# STM32H745BGT6@M4 register map
File version: 1.0
Registers are 32-bit, access not given, reset 0x0 unless marked. A register's access mark holds for its fields unless they carry their own. Offsets are from the block's base; [hi:lo] are bit positions.

## TIM6
Base 0x40001000
Same registers: TIM7 0x40001400
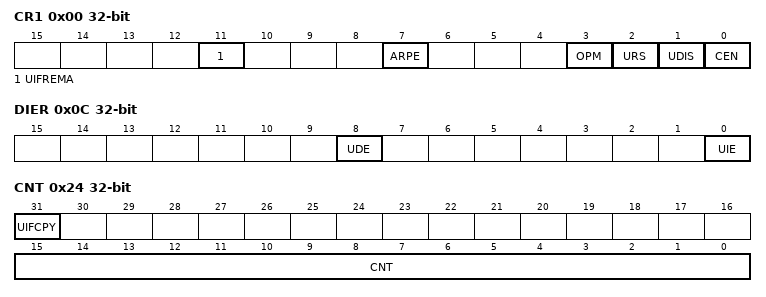
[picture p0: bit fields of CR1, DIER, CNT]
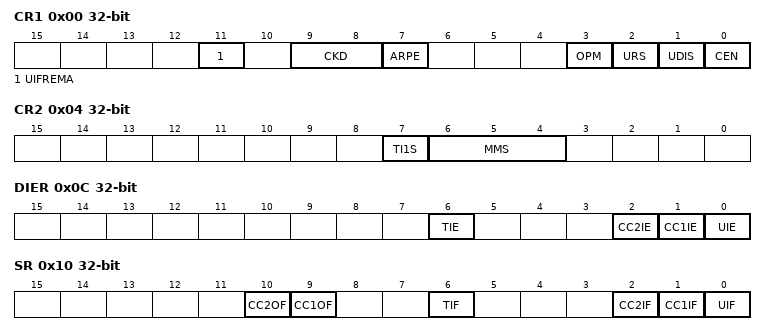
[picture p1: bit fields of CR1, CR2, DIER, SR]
0x00 CR1
  [11] UIFREMA, [7] ARPE, [3] OPM, [2] URS, [1] UDIS, [0] CEN
0x04 CR2
  [6:4] MMS
0x0C DIER
  [8] UDE, [0] UIE
0x10 SR
  [0] UIF
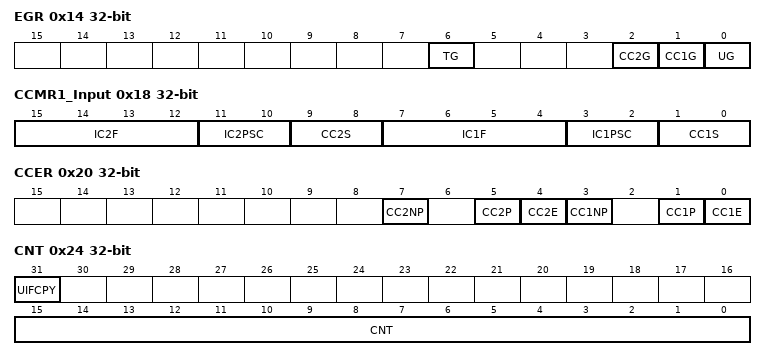
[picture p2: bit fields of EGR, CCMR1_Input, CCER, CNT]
0x14 EGR
  [0] UG
0x24 CNT
  [31] UIFCPY, [15:0] CNT
0x28 PSC
  [15:0] PSC
0x2C ARR
  [15:0] ARR

## TIM12
Base 0x40001800
0x00 CR1
  [11] UIFREMA, [9:8] CKD, [7] ARPE, [3] OPM, [2] URS, [1] UDIS, [0] CEN
0x04 CR2
  [7] TI1S, [6:4] MMS
0x08 SMCR
  [7] MSM, [21:4] TS, [16:0] SMS
0x0C DIER
  [6] TIE, [2] CC2IE, [1] CC1IE, [0] UIE
0x10 SR
  [10] CC2OF, [9] CC1OF, [6] TIF, [2] CC2IF, [1] CC1IF, [0] UIF
0x14 EGR
  [6] TG, [2] CC2G, [1] CC1G, [0] UG
0x18 CCMR1_Output
  [24:12] OC2M, [11] OC2PE, [10] OC2FE, [9:8] CC2S, [16:4] OC1M, [3] OC1PE, [2] OC1FE, [1:0] CC1S
0x18 CCMR1_Input
  [15:12] IC2F, [11:10] IC2PSC, [9:8] CC2S, [7:4] IC1F, [3:2] IC1PSC, [1:0] CC1S
0x20 CCER
  [7] CC2NP, [5] CC2P, [4] CC2E, [3] CC1NP, [1] CC1P, [0] CC1E
0x24 CNT
  [31] UIFCPY, [15:0] CNT
0x28 PSC
  [15:0] PSC
0x2C ARR
  [15:0] ARR
0x34 CCR1
  [15:0] CCR1
0x38 CCR2
  [15:0] CCR2
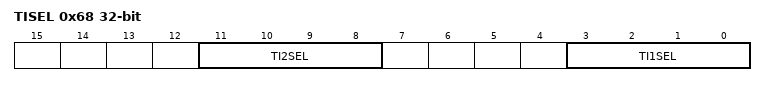
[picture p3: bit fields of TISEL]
0x68 TISEL
  [11:8] TI2SEL, [3:0] TI1SEL

## TIM13
Base 0x40001C00
Same registers: TIM14 0x40002000
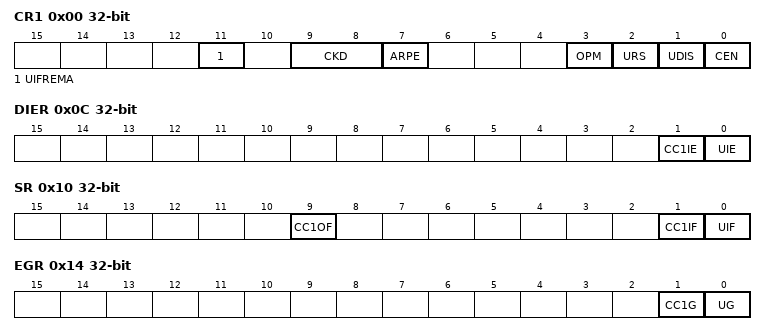
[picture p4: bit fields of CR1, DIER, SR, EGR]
0x00 CR1
  [11] UIFREMA, [9:8] CKD, [7] ARPE, [3] OPM, [2] URS, [1] UDIS, [0] CEN
0x0C DIER
  [1] CC1IE, [0] UIE
0x10 SR
  [9] CC1OF, [1] CC1IF, [0] UIF
0x14 EGR
  [1] CC1G, [0] UG
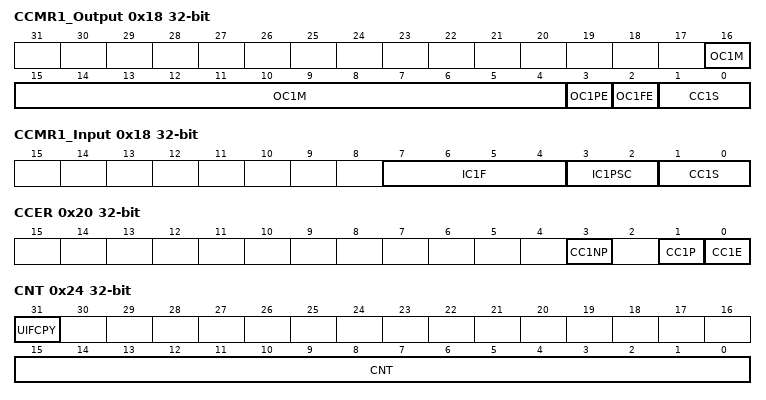
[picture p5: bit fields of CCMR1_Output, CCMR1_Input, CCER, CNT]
0x18 CCMR1_Output
  [16:4] OC1M, [3] OC1PE, [2] OC1FE, [1:0] CC1S
0x18 CCMR1_Input
  [7:4] IC1F, [3:2] IC1PSC, [1:0] CC1S
0x20 CCER
  [3] CC1NP, [1] CC1P, [0] CC1E
0x24 CNT
  [31] UIFCPY, [15:0] CNT
0x28 PSC
  [15:0] PSC
0x2C ARR
  [15:0] ARR
0x34 CCR1
  [15:0] CCR1
0x68 TISEL
  [3:0] TI1SEL

## LPTIM1
Base 0x40002400
Same registers: LPTIM2 0x58002400, LPTIM4 0x58002C00, LPTIM5 0x58003000
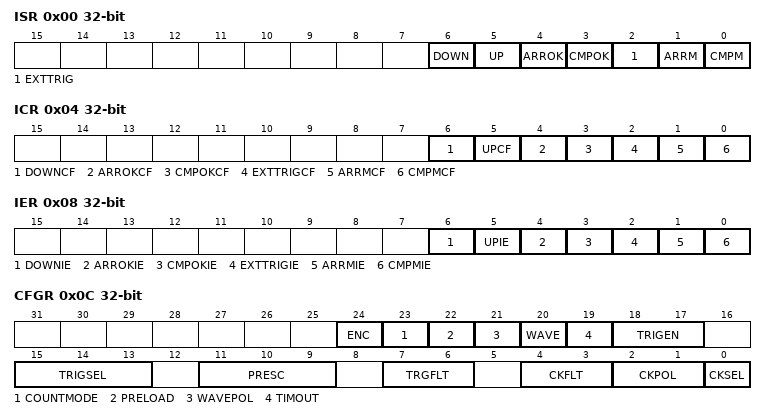
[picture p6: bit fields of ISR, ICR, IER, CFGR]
0x00 ISR
  [6] DOWN, [5] UP, [4] ARROK, [3] CMPOK, [2] EXTTRIG, [1] ARRM, [0] CMPM
0x04 ICR
  [6] DOWNCF, [5] UPCF, [4] ARROKCF, [3] CMPOKCF, [2] EXTTRIGCF, [1] ARRMCF, [0] CMPMCF
0x08 IER
  [6] DOWNIE, [5] UPIE, [4] ARROKIE, [3] CMPOKIE, [2] EXTTRIGIE, [1] ARRMIE, [0] CMPMIE
0x0C CFGR
  [24] ENC, [23] COUNTMODE, [22] PRELOAD, [21] WAVEPOL, [20] WAVE, [19] TIMOUT, [18:17] TRIGEN, [15:13] TRIGSEL, [11:9] PRESC, [7:6] TRGFLT, [4:3] CKFLT, [2:1] CKPOL, [0] CKSEL
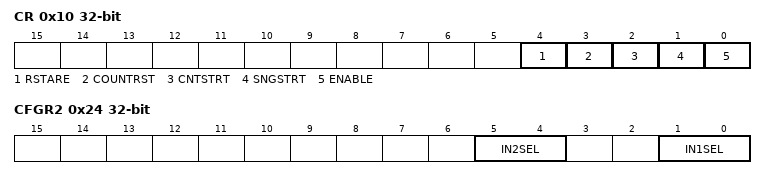
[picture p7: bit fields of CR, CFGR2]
0x10 CR
  [4] RSTARE, [3] COUNTRST, [2] CNTSTRT, [1] SNGSTRT, [0] ENABLE
0x14 CMP
  [15:0] CMP
0x18 ARR
  [15:0] ARR
0x1C CNT
  [15:0] CNT
0x24 CFGR2
  [5:4] IN2SEL, [1:0] IN1SEL

## LPTIM3
Base 0x58002800
Registers as LPTIM1; these are added or differ:
0x24 CFGR2
  [1:0] IN1SEL

## WWDG2
Base 0x40002C00
Same registers: WWDG1 0x50003000
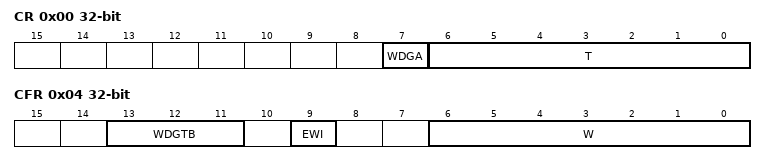
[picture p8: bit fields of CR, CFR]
0x00 CR
  [7] WDGA, [6:0] T
0x04 CFR
  [13:11] WDGTB, [9] EWI, [6:0] W
0x08 SR
  [0] EWIF

## SPI2
Base 0x40003800
Same registers: SPI3 0x40003C00, SPI1 0x40013000, SPI4 0x40013400, SPI5 0x40015000, SPI6 0x58001400
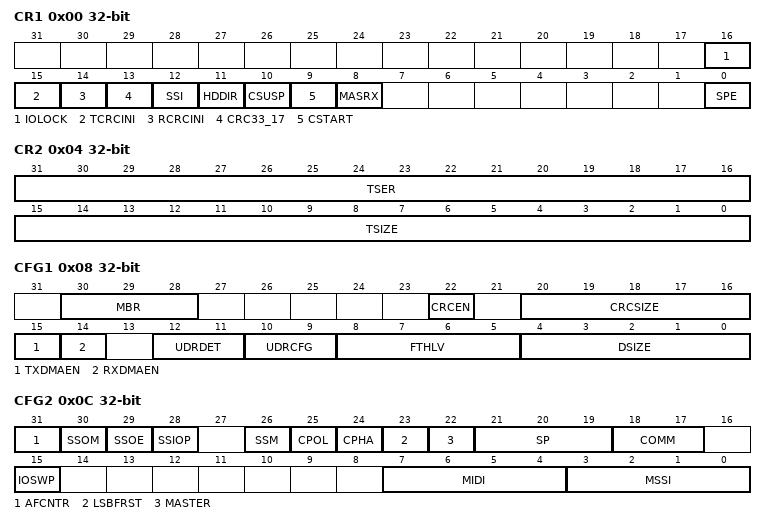
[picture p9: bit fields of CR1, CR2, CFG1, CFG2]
0x00 CR1
  [16] IOLOCK, [15] TCRCINI, [14] RCRCINI, [13] CRC33_17, [12] SSI, [11] HDDIR, [10] CSUSP, [9] CSTART, [8] MASRX, [0] SPE
0x04 CR2
  [31:16] TSER, [15:0] TSIZE
0x08 CFG1
  [30:28] MBR, [22] CRCEN, [20:16] CRCSIZE, [15] TXDMAEN, [14] RXDMAEN, [12:11] UDRDET, [10:9] UDRCFG, [8:5] FTHLV, [4:0] DSIZE
0x0C CFG2
  [31] AFCNTR, [30] SSOM, [29] SSOE, [28] SSIOP, [26] SSM, [25] CPOL, [24] CPHA, [23] LSBFRST, [22] MASTER, [21:19] SP, [18:17] COMM, [15] IOSWP, [7:4] MIDI, [3:0] MSSI
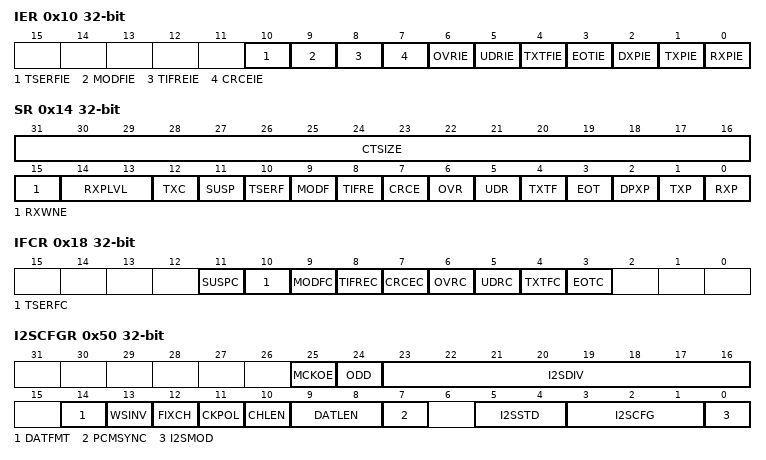
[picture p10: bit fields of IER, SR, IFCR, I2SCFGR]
0x10 IER
  [10] TSERFIE, [9] MODFIE, [8] TIFREIE, [7] CRCEIE, [6] OVRIE, [5] UDRIE, [4] TXTFIE, [3] EOTIE, [2] DXPIE, [1] TXPIE, [0] RXPIE
0x14 SR
  [31:16] CTSIZE, [15] RXWNE, [14:13] RXPLVL, [12] TXC, [11] SUSP, [10] TSERF, [9] MODF, [8] TIFRE, [7] CRCE, [6] OVR, [5] UDR, [4] TXTF, [3] EOT, [2] DPXP, [1] TXP, [0] RXP
0x18 IFCR
  [11] SUSPC, [10] TSERFC, [9] MODFC, [8] TIFREC, [7] CRCEC, [6] OVRC, [5] UDRC, [4] TXTFC, [3] EOTC
0x20 TXDR
0x30 RXDR
0x40 CRCPOLY
0x44 TXCRC
0x48 RXCRC
0x4C UDRDR
0x50 I2SCFGR
  [25] MCKOE, [24] ODD, [23:16] I2SDIV, [14] DATFMT, [13] WSINV, [12] FIXCH, [11] CKPOL, [10] CHLEN, [9:8] DATLEN, [7] PCMSYNC, [5:4] I2SSTD, [3:1] I2SCFG, [0] I2SMOD
